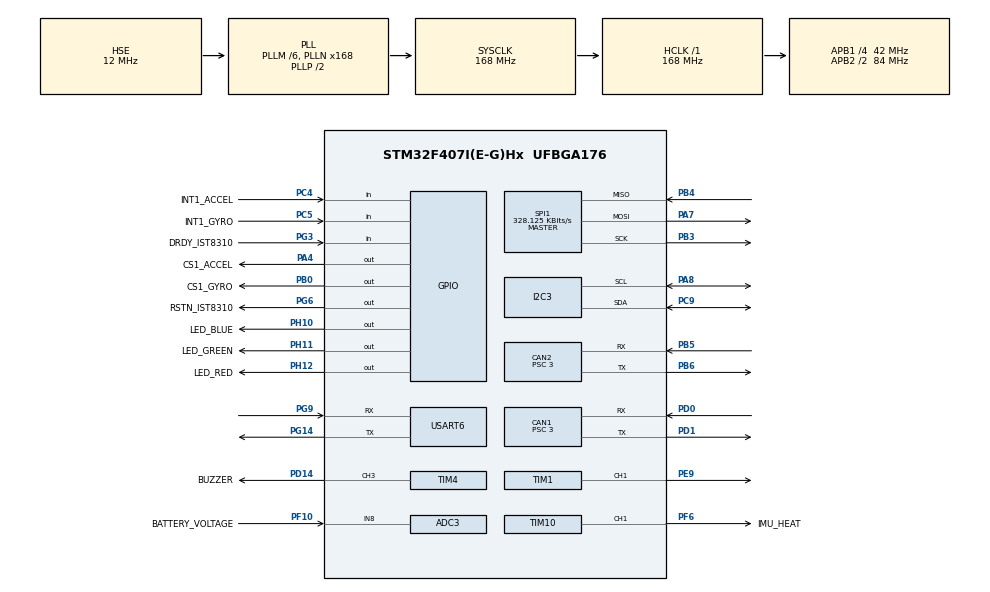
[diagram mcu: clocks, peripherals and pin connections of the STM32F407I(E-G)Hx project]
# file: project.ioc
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ADC3.Channel-0\#ChannelRegularConversion=ADC_CHANNEL_8
ADC3.ClockPrescaler=ADC_CLOCK_SYNC_PCLK_DIV4
ADC3.ContinuousConvMode=DISABLE
ADC3.DMAContinuousRequests=DISABLE
ADC3.DataAlign=ADC_DATAALIGN_RIGHT
ADC3.DiscontinuousConvMode=DISABLE
ADC3.EOCSelection=ADC_EOC_SINGLE_CONV
ADC3.ExternalTrigConv=ADC_SOFTWARE_START
ADC3.ExternalTrigConvEdge=ADC_EXTERNALTRIGCONVEDGE_NONE
ADC3.NbrOfConversion=1
ADC3.NbrOfConversionFlag=1
ADC3.Rank-0\#ChannelRegularConversion=1
ADC3.Resolution=ADC_RESOLUTION_12B
ADC3.SamplingTime-0\#ChannelRegularConversion=ADC_SAMPLETIME_480CYCLES
ADC3.ScanConvMode=DISABLE
CAN1.ABOM=ENABLE
CAN1.AWUM=DISABLE
CAN1.BS1=CAN_BS1_10TQ
CAN1.BS2=CAN_BS2_3TQ
CAN1.CalculateBaudRate=1000000
CAN1.CalculateTimeBit=1000
CAN1.CalculateTimeQuantum=71.42857142857143
CAN1.NART=ENABLE
CAN1.Prescaler=3
CAN2.ABOM=ENABLE
CAN2.AWUM=DISABLE
CAN2.BS1=CAN_BS1_10TQ
CAN2.BS2=CAN_BS2_3TQ
CAN2.CalculateBaudRate=1000000
CAN2.CalculateTimeBit=1000
CAN2.CalculateTimeQuantum=71.42857142857143
CAN2.NART=ENABLE
CAN2.Prescaler=3
Dma.Request0=USART6_TX
Dma.USART6_TX.0.Direction=DMA_MEMORY_TO_PERIPH
Dma.USART6_TX.0.FIFOMode=DMA_FIFOMODE_DISABLE
Dma.USART6_TX.0.Instance=DMA2_Stream7
Dma.USART6_TX.0.MemDataAlignment=DMA_MDATAALIGN_BYTE
Dma.USART6_TX.0.MemInc=DMA_MINC_ENABLE
Dma.USART6_TX.0.Mode=DMA_NORMAL
Dma.USART6_TX.0.PeriphDataAlignment=DMA_PDATAALIGN_BYTE
Dma.USART6_TX.0.PeriphInc=DMA_PINC_DISABLE
Dma.USART6_TX.0.Priority=DMA_PRIORITY_LOW
FREERTOS.INCLUDE_uxTaskGetStackHighWaterMark=1
FREERTOS.INCLUDE_vTaskDelayUntil=1
FREERTOS.Tasks01=test,0,512,test_task,As weak,NULL,Dynamic,NULL,NULL;imuTask,2,1024,INS_task,As weak,NULL,Dynamic,NULL,NULL
FREERTOS.configTOTAL_HEAP_SIZE=24576
I2C3.I2C_Mode=I2C_Fast
Mcu.Family=STM32F4
Mcu.Name=STM32F407I(E-G)Hx
Mcu.Package=UFBGA176
NVIC.CAN1_RX0_IRQn=true\:6\:0\:true\:false\:true\:true\:true\:true\:true
NVIC.CAN2_RX0_IRQn=true\:6\:0\:true\:false\:true\:true\:true\:true\:true
NVIC.DMA2_Stream7_IRQn=true\:6\:0\:true\:false\:true\:true\:true\:true\:true
NVIC.PriorityGroup=NVIC_PRIORITYGROUP_4
NVIC.TIM6_DAC_IRQn=true\:15\:0\:false\:false\:true\:false\:false\:true\:true
NVIC.TimeBase=TIM6_DAC_IRQn
NVIC.TimeBaseIP=TIM6
NVIC.USART6_IRQn=true\:5\:0\:false\:false\:true\:true\:true\:true\:true
PA13.Mode=Serial_Wire
PA13.Signal=SYS_JTMS-SWDIO
PA14.Mode=Serial_Wire
PA14.Signal=SYS_JTCK-SWCLK
PA4.GPIO_Label=CS1_ACCEL
PA4.GPIO_Speed=GPIO_SPEED_FREQ_HIGH
PA4.PinState=GPIO_PIN_SET
PA4.Signal=GPIO_Output
PA7.Mode=Full_Duplex_Master
PA7.Signal=SPI1_MOSI
PA8.Mode=I2C
PA8.Signal=I2C3_SCL
PB0.GPIO_Label=CS1_GYRO
PB0.GPIO_Speed=GPIO_SPEED_FREQ_HIGH
PB0.PinState=GPIO_PIN_SET
PB0.Signal=GPIO_Output
PB3.Mode=Full_Duplex_Master
PB3.Signal=SPI1_SCK
PB4.Mode=Full_Duplex_Master
PB4.Signal=SPI1_MISO
PB5.Mode=CAN_Activate
PB5.Signal=CAN2_RX
PB6.Mode=CAN_Activate
PB6.Signal=CAN2_TX
PC4.GPIO_Label=INT1_ACCEL
PC4.Signal=GPIO_Input
PC5.GPIO_Label=INT1_GYRO
PC5.Signal=GPIO_Input
PC9.Mode=I2C
PC9.Signal=I2C3_SDA
PD0.Mode=CAN_Activate
PD0.Signal=CAN1_RX
PD1.Mode=CAN_Activate
PD1.Signal=CAN1_TX
PD14.GPIO_Label=BUZZER
PD14.GPIO_PuPd=GPIO_PULLDOWN
PD14.GPIO_Speed=GPIO_SPEED_FREQ_LOW
PD14.Signal=S_TIM4_CH3
PE9.Signal=S_TIM1_CH1
PF10.GPIO_Label=BATTERY_VOLTAGE
PF10.Mode=IN8
PF10.Signal=ADC3_IN8
PF6.GPIO_Label=IMU_HEAT
PF6.GPIO_PuPd=GPIO_PULLDOWN
PF6.GPIO_Speed=GPIO_SPEED_FREQ_LOW
PF6.Signal=S_TIM10_CH1
PG14.Mode=Asynchronous
PG14.Signal=USART6_TX
PG3.GPIO_Label=DRDY_IST8310
PG3.GPIO_PuPd=GPIO_PULLUP
PG3.Signal=GPIO_Input
PG6.GPIO_Label=RSTN_IST8310
PG6.GPIO_PuPd=GPIO_PULLUP
PG6.GPIO_Speed=GPIO_SPEED_FREQ_MEDIUM
PG6.PinState=GPIO_PIN_SET
PG6.Signal=GPIO_Output
PG9.Mode=Asynchronous
PG9.Signal=USART6_RX
PH0-OSC_IN.Mode=HSE-External-Oscillator
PH0-OSC_IN.Signal=RCC_OSC_IN
PH1-OSC_OUT.Mode=HSE-External-Oscillator
PH1-OSC_OUT.Signal=RCC_OSC_OUT
PH10.GPIO_Label=LED_BLUE
PH10.GPIO_PuPd=GPIO_NOPULL
PH10.GPIO_Speed=GPIO_SPEED_FREQ_LOW
PH10.PinState=GPIO_PIN_RESET
PH10.Signal=GPIO_Output
PH11.GPIO_Label=LED_GREEN
PH11.GPIO_PuPd=GPIO_NOPULL
PH11.GPIO_Speed=GPIO_SPEED_FREQ_LOW
PH11.PinState=GPIO_PIN_RESET
PH11.Signal=GPIO_Output
PH12.GPIO_Label=LED_RED
PH12.GPIO_PuPd=GPIO_NOPULL
PH12.GPIO_Speed=GPIO_SPEED_FREQ_LOW
PH12.PinState=GPIO_PIN_RESET
PH12.Signal=GPIO_Output
ProjectManager.HeapSize=0x200
ProjectManager.StackSize=0x1000
ProjectManager.TargetToolchain=CMake
RCC.48MHZClocksFreq_Value=48000000
RCC.ADCFreq_Value=21000000
RCC.AHBFreq_Value=168000000
RCC.APB1CLKDivider=RCC_HCLK_DIV4
RCC.APB1Freq_Value=42000000
RCC.APB1TimFreq_Value=84000000
RCC.APB2CLKDivider=RCC_HCLK_DIV2
RCC.APB2Freq_Value=84000000
RCC.APB2TimFreq_Value=168000000
RCC.CortexFreq_Value=168000000
RCC.HCLKFreq_Value=168000000
RCC.HSE_VALUE=12000000
RCC.HSI_VALUE=16000000
RCC.LSE_VALUE=32768
RCC.PLLM=6
RCC.PLLN=168
RCC.PLLQ=7
RCC.PLLSourceVirtual=RCC_PLLSOURCE_HSE
RCC.SYSCLKFreq_VALUE=168000000
RCC.SYSCLKSource=RCC_SYSCLKSOURCE_PLLCLK
RCC.VCOOutputFreq_Value=336000000
SH.S_TIM10_CH1.0=TIM10_CH1,PWM Generation1 CH1
SH.S_TIM1_CH1.0=TIM1_CH1,PWM Generation1 CH1
SH.S_TIM4_CH3.0=TIM4_CH3,PWM Generation3 CH3
SPI1.BaudRatePrescaler=SPI_BAUDRATEPRESCALER_256
SPI1.CLKPhase=SPI_PHASE_2EDGE
SPI1.CLKPolarity=SPI_POLARITY_HIGH
SPI1.CalculateBaudRate=328.125 KBits/s
SPI1.Direction=SPI_DIRECTION_2LINES
SPI1.Mode=SPI_MODE_MASTER
SPI1.VirtualType=VM_MASTER
TIM1.Channel-PWM\ Generation1\ CH1=TIM_CHANNEL_1
TIM1.Period=19999
TIM1.Prescaler=167
TIM10.Channel=TIM_CHANNEL_1
TIM10.Period=4999
TIM10.Prescaler=167
TIM2.Prescaler=83
TIM4.Channel-PWM\ Generation3\ CH3=TIM_CHANNEL_3
TIM4.Period=249
TIM4.Prescaler=83
USART6.VirtualMode=VM_ASYNC
VP_FREERTOS_VS_CMSIS_V1.Mode=CMSIS_V1
VP_SYS_VS_tim6.Mode=TIM6
VP_TIM10_VS_ClockSourceINT.Mode=Enable_Timer
VP_TIM1_VS_ClockSourceINT.Mode=Internal
VP_TIM2_VS_ClockSourceINT.Mode=Internal
VP_TIM4_VS_ClockSourceINT.Mode=Internal
board=custom

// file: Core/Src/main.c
/* USER CODE BEGIN Header */
/**
  ******************************************************************************
  * @file           : main.c
  * @brief          : Main program body
  ******************************************************************************
  * @attention
  *
  * Copyright (c) 2026 STMicroelectronics.
  * All rights reserved.
  *
  * This software is licensed under terms that can be found in the LICENSE file
  * in the root directory of this software component.
  * If no LICENSE file comes with this software, it is provided AS-IS.
  *
  ******************************************************************************
  */
/* USER CODE END Header */
#include "main.h"
#include "cmsis_os.h"
#include "adc.h"
#include "can.h"
#include "dma.h"
#include "i2c.h"
#include "spi.h"
#include "tim.h"
#include "usart.h"
#include "gpio.h"

void SystemClock_Config(void);
void MX_FREERTOS_Init(void);

int main(void)
{

  /* MCU Configuration--------------------------------------------------------*/

  /* Reset of all peripherals, Initializes the Flash interface and the Systick. */
  HAL_Init();

  /* Configure the system clock */
  SystemClock_Config();

  /* Initialize all configured peripherals */
  MX_GPIO_Init();
  MX_DMA_Init();
  MX_CAN1_Init();
  MX_CAN2_Init();
  MX_I2C3_Init();
  MX_SPI1_Init();
  MX_TIM2_Init();
  MX_USART6_UART_Init();
  MX_ADC3_Init();
  MX_TIM4_Init();
  MX_TIM10_Init();
  MX_TIM1_Init();

  /* Call init function for freertos objects (in cmsis_os2.c) */
  MX_FREERTOS_Init();

  /* Start scheduler */
  osKernelStart();

  /* We should never get here as control is now taken by the scheduler */

  /* Infinite loop */
  while (1)
  {

  }
}

void SystemClock_Config(void)
{
  RCC_OscInitTypeDef RCC_OscInitStruct = {0};
  RCC_ClkInitTypeDef RCC_ClkInitStruct = {0};

  /** Configure the main internal regulator output voltage
  */
  __HAL_RCC_PWR_CLK_ENABLE();
  __HAL_PWR_VOLTAGESCALING_CONFIG(PWR_REGULATOR_VOLTAGE_SCALE1);

  /** Initializes the RCC Oscillators according to the specified parameters
  * in the RCC_OscInitTypeDef structure.
  */
  RCC_OscInitStruct.OscillatorType = RCC_OSCILLATORTYPE_HSE;
  RCC_OscInitStruct.HSEState = RCC_HSE_ON;
  RCC_OscInitStruct.PLL.PLLState = RCC_PLL_ON;
  RCC_OscInitStruct.PLL.PLLSource = RCC_PLLSOURCE_HSE;
  RCC_OscInitStruct.PLL.PLLM = 6;
  RCC_OscInitStruct.PLL.PLLN = 168;
  RCC_OscInitStruct.PLL.PLLP = RCC_PLLP_DIV2;
  RCC_OscInitStruct.PLL.PLLQ = 7;
  if (HAL_RCC_OscConfig(&RCC_OscInitStruct) != HAL_OK)
  {
    Error_Handler();
  }

  /** Initializes the CPU, AHB and APB buses clocks
  */
  RCC_ClkInitStruct.ClockType = RCC_CLOCKTYPE_HCLK|RCC_CLOCKTYPE_SYSCLK
                              |RCC_CLOCKTYPE_PCLK1|RCC_CLOCKTYPE_PCLK2;
  RCC_ClkInitStruct.SYSCLKSource = RCC_SYSCLKSOURCE_PLLCLK;
  RCC_ClkInitStruct.AHBCLKDivider = RCC_SYSCLK_DIV1;
  RCC_ClkInitStruct.APB1CLKDivider = RCC_HCLK_DIV4;
  RCC_ClkInitStruct.APB2CLKDivider = RCC_HCLK_DIV2;

  if (HAL_RCC_ClockConfig(&RCC_ClkInitStruct, FLASH_LATENCY_5) != HAL_OK)
  {
    Error_Handler();
  }
}

void HAL_TIM_PeriodElapsedCallback(TIM_HandleTypeDef *htim)
{
  if (htim->Instance == TIM6)
  {
    HAL_IncTick();
  }
}

void Error_Handler(void)
{
  __disable_irq();
  while (1)
  {
  }
}

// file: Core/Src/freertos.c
/* USER CODE BEGIN Header */
/**
  ******************************************************************************
  * File Name          : freertos.c
  * Description        : Code for freertos applications
  ******************************************************************************
  * @attention
  *
  * Copyright (c) 2026 STMicroelectronics.
  * All rights reserved.
  *
  * This software is licensed under terms that can be found in the LICENSE file
  * in the root directory of this software component.
  * If no LICENSE file comes with this software, it is provided AS-IS.
  *
  ******************************************************************************
  */
/* USER CODE END Header */

#include "FreeRTOS.h"
#include "task.h"
#include "main.h"
#include "cmsis_os.h"

/* USER CODE BEGIN Includes */
#include "usb_link.h"
/* USER CODE END Includes */

osThreadId testHandle;
osThreadId imuTaskHandle;

void test_task(void const * argument);
void INS_task(void const * argument);

void MX_FREERTOS_Init(void); /* (MISRA C 2004 rule 8.1) */

/* GetIdleTaskMemory prototype (linked to static allocation support) */
void vApplicationGetIdleTaskMemory( StaticTask_t **ppxIdleTaskTCBBuffer, StackType_t **ppxIdleTaskStackBuffer, uint32_t *pulIdleTaskStackSize );

/* USER CODE BEGIN GET_IDLE_TASK_MEMORY */
static StaticTask_t xIdleTaskTCBBuffer;
static StackType_t xIdleStack[configMINIMAL_STACK_SIZE];

void vApplicationGetIdleTaskMemory( StaticTask_t **ppxIdleTaskTCBBuffer, StackType_t **ppxIdleTaskStackBuffer, uint32_t *pulIdleTaskStackSize )
{
  *ppxIdleTaskTCBBuffer = &xIdleTaskTCBBuffer;
  *ppxIdleTaskStackBuffer = &xIdleStack[0];
  *pulIdleTaskStackSize = configMINIMAL_STACK_SIZE;
  /* place for user code */
}
/* USER CODE END GET_IDLE_TASK_MEMORY */

void MX_FREERTOS_Init(void) {
  /* USER CODE BEGIN Init */
#if !UART6_MANUAL_ENABLED
  /* The USB HAL needs TIM6 for HAL_Delay. Creating the first FreeRTOS task masks
     TIM6 until the scheduler starts, so complete USB setup before creating tasks. */
  const uint8_t usb_ready = UsbLink_Init();
#endif
  /* USER CODE END Init */

  /* Create the thread(s) */
  /* definition and creation of test */
  osThreadDef(test, test_task, osPriorityNormal, 0, 512);
  testHandle = osThreadCreate(osThread(test), NULL);

  /* definition and creation of imuTask */
  osThreadDef(imuTask, INS_task, osPriorityHigh, 0, 1024);
  imuTaskHandle = osThreadCreate(osThread(imuTask), NULL);

  /* USER CODE BEGIN RTOS_THREADS */
#if !UART6_MANUAL_ENABLED
  /* USB 组帧低于底盘任务，避免读阻塞 5 ms 控制拍。 */
  if (usb_ready)
  {
    osThreadDef(usbLink, UsbLink_Task, osPriorityBelowNormal, 0, 512);
    osThreadCreate(osThread(usbLink), NULL);
  }
#endif
  /* USER CODE END RTOS_THREADS */

}

__weak void test_task(void const * argument)
{
  for(;;)
  {
    osDelay(1);
  }
}

__weak void INS_task(void const * argument)
{
  for(;;)
  {
    osDelay(1);
  }
}
